# EFR32FG23A010F128GM40 register map
Vendor: Silicon Labs; Series: EFR32; File version: B
Registers are 32-bit, read-write, reset 0x0 unless marked. A register's access mark holds for its fields unless they carry their own. Offsets are from the block's base; [hi:lo] are bit positions; {n}, {i} and the like mark numbered series.

## DMEM_S — DMEM_S Registers
Base 0x400B4000
Same registers: DMEM_NS 0x500B4000
0x00 IPVERSION ro reset 0x1
  [0] IPVERSION — New BitField
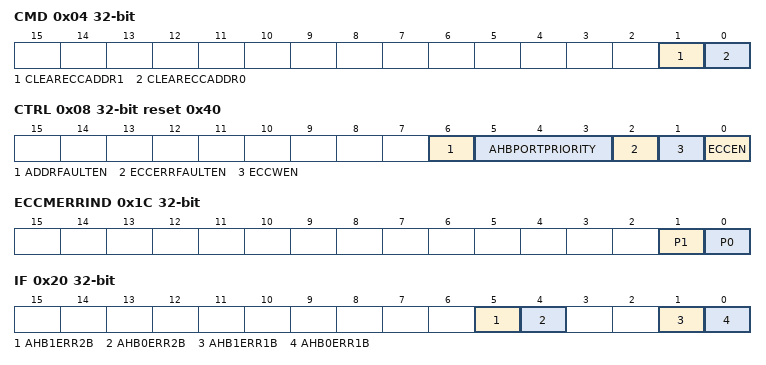
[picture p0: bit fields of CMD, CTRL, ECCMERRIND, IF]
0x04 CMD wo
  [1] CLEARECCADDR1 — Clear ECCERRADDR1
  [0] CLEARECCADDR0 — Clear ECCERRADDR0
0x08 CTRL reset 0x40
  [6] ADDRFAULTEN — Address fault bus fault enable
  [5:3] AHBPORTPRIORITY — AHB port arbitration priority
    0=NONE (No AHB port have raised priority.); 1=PORT0 (AHB port 0 has raised priority.); 2=PORT1 (AHB port 1 has raised priority.)
  [2] ECCERRFAULTEN — ECC Error bus fault enable
  [1] ECCWEN — Enable ECC syndrome writes
  [0] ECCEN — Enable ECC functionality
0x0C ECCERRADDR0 ro
  [31:0] ADDR — ECC Error Address
0x10 ECCERRADDR1 ro
  [31:0] ADDR — ECC Error Address
0x1C ECCMERRIND ro
  [1] P1 — Multiple ECC errors on AHB port 1
  [0] P0 — Multiple ECC errors on AHB port 0
0x20 IF
  [5] AHB1ERR2B — AHB1 2-bit ECC Error Interrupt Flag
  [4] AHB0ERR2B — AHB0 2-bit ECC Error Interrupt Flag
  [1] AHB1ERR1B — AHB1 1-bit ECC Error Interrupt Flag
  [0] AHB0ERR1B — AHB0 1-bit ECC Error Interrupt Flag
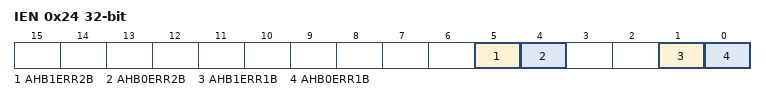
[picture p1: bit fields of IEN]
0x24 IEN
  [5] AHB1ERR2B — AHB1 2-bit ECC Error Interrupt Enable
  [4] AHB0ERR2B — AHB0 2-bit ECC Error Interrupt Enable
  [1] AHB1ERR1B — AHB1 1-bit ECC Error Interrupt Enable
  [0] AHB0ERR1B — AHB0 1-bit ECC Error Interrupt Enable

## LCDRF_S — LCDRF_S Registers
Base 0x400C0000
Same registers: LCDRF_NS 0x500C0000
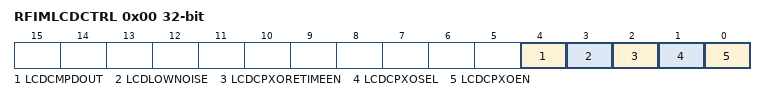
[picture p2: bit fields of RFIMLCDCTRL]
0x00 RFIMLCDCTRL
  [4] LCDCMPDOUT — LCD Comparator Dout
  [3] LCDLOWNOISE
    0=NORMAL (Normal operation); 1=SLOW (slows down slew rate to reduce RF interference at a cost of additional power consumption)
  [2] LCDCPXORETIMEEN — LCD Charge Pump XO Retime Enable
  [1] LCDCPXOSEL — LCD Charge Pump XO Select
    0=INTRCO (Internal LCD CP 10Mhz RC oscillator); 1=HFXODIV (HFXO divided 4 clock)
  [0] LCDCPXOEN — LCD Charge Pump XO Clock Enable

## PFMXPPRF_S — PFMXPPRF_S Registers
Base 0x400C4000
Same registers: PFMXPPRF_NS 0x500C4000
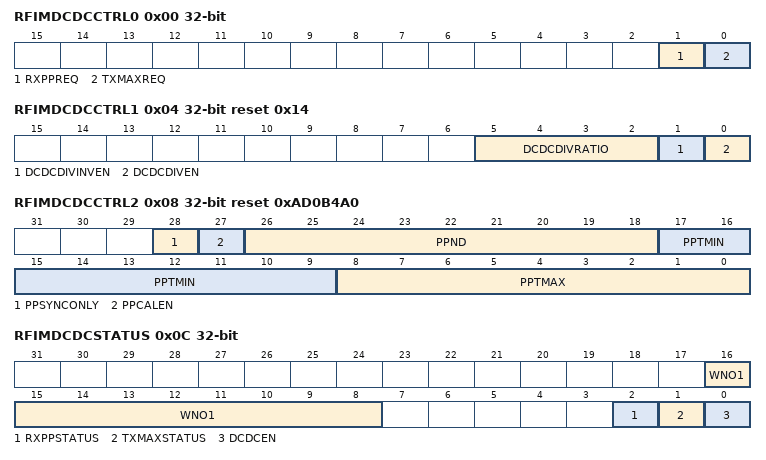
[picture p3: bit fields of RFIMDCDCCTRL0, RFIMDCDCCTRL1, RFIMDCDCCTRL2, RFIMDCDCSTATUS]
0x00 RFIMDCDCCTRL0
  [1] RXPPREQ, [0] TXMAXREQ
0x04 RFIMDCDCCTRL1 reset 0x14
  [5:2] DCDCDIVRATIO
    0=DIVRATIO8 (Dividing master_rf clk by 8, D=50%); 1=DIVRATIO9 (Dividing master_rf clk by 9, D=44.4%); 2=DIVRATIO10 (Dividing master_rf clk by 10, D=40%); 3=DIVRATIO11 (Dividing master_rf clk by 11, D=36.4%); 4=DIVRATIO12 (Dividing master_rf clk by 12, D=50%); 5=DIVRATIO13 (Dividing master_rf clk by 13, D=46.2%); 6=DIVRATIO14 (Dividing master_rf clk by 14, D=42.9%); 7=DIVRATIO15 (Dividing master_rf clk by 15, D=40%); 8=DIVRATIO16 (Dividing master_rf clk by 16, D=50%); 9=DIVRATIO17 (Dividing master_rf clk by 17, D=47.1%); 10=DIVRATIO18 (Dividing master_rf clk by 18, D=44.4%); 11=DIVRATIO19 (Dividing master_rf clk by 19, D=42.1%); 12=DIVRATIO20 (Dividing master_rf clk by 20, D=60%); 13=DIVRATIO21 (Dividing master_rf clk by 21, D=57.1%); 14=DIVRATIO22 (Dividing master_rf clk by 22, D=54.5%); 15=DIVRATIO23 (Dividing master_rf clk by 23, D=52.2%)
  [1] DCDCDIVINVEN — DCDC DIV Inverter Enable
  [0] DCDCDIVEN — DCDC DIV Enable
0x08 RFIMDCDCCTRL2 reset 0xAD0B4A0
  [28] PPSYNCONLY — Pulse Pairing Sync Only
  [27] PPCALEN — Pulse Pairing Calibration Loop Enable
  [26:18] PPND — Pulse Pairing Period
  [17:9] PPTMIN — Pulse Pairing Time Min
  [8:0] PPTMAX — Pulse Pairing Time Max
0x0C RFIMDCDCSTATUS ro
  [16:8] WNO1 — Cal Loop WNO1 value
  [2] RXPPSTATUS
  [1] TXMAXSTATUS
  [0] DCDCEN — DCDC Enable Status
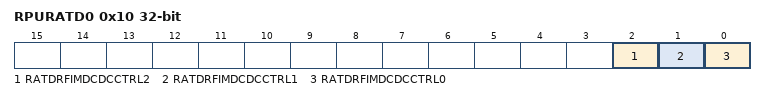
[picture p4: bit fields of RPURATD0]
0x10 RPURATD0 — Protected register address = (RPURATD register index X 32 + RPURATD bit index) X 4.
  [2] RATDRFIMDCDCCTRL2 — RFIMDCDCCTRL2 Protection Bit
  [1] RATDRFIMDCDCCTRL1 — RFIMDCDCCTRL1 Protection Bit
  [0] RATDRFIMDCDCCTRL0 — RFIMDCDCCTRL0 Protection Bit

## SMU_S_CFGNS — SMU_S_CFGNS Registers
Base 0x4400C000
Same registers: SMU_NS_CFGNS 0x5400C000
0x04 NSSTATUS ro
  [0] SMUNSLOCK
    0=UNLOCKED; 1=LOCKED
0x08 NSLOCK wo
  [23:0] SMUNSLOCKKEY
    0xACCE55=UNLOCK (Unlocks Registers)
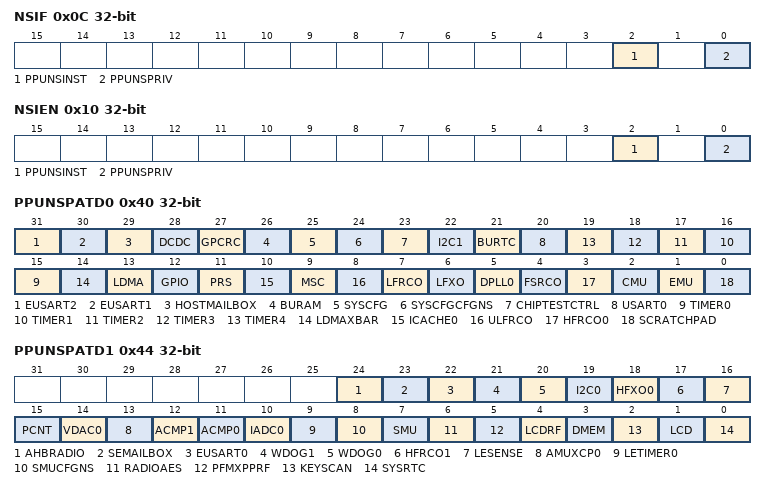
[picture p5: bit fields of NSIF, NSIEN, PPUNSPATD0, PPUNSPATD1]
0x0C NSIF
  [2] PPUNSINST — PPUNS Instruction Interrupt Flag
  [0] PPUNSPRIV — PPUNS Privilege Interrupt Flag
0x10 NSIEN
  [2] PPUNSINST — PPUNS Instruction Interrupt Enable
  [0] PPUNSPRIV — PPUNS Privilege Interrupt Enable
0x40 PPUNSPATD0 — Set peripheral bits to 1 to mark as privileged access only
  [31] EUSART2 — EUSART2 Privileged Access
  [30] EUSART1 — EUSART1 Privileged Access
  [29] HOSTMAILBOX — HOSTMAILBOX Privileged Access
  [28] DCDC — DCDC Privileged Access
  [27] GPCRC — GPCRC Privileged Access
  [26] BURAM — BURAM Privileged Access
  [25] SYSCFG — SYSCFG Privileged Access
  [24] SYSCFGCFGNS — SYSCFGCFGNS Privileged Access
  [23] CHIPTESTCTRL — CHIPTESTCTRL Privileged Access
  [22] I2C1 — I2C1 Privileged Access
  [21] BURTC — BURTC Privileged Access
  [20] USART0 — USART0 Privileged Access
  [n+15] TIMER{n} (n=0..4) — TIMER{n} Privileged Access
  [14] LDMAXBAR — LDMAXBAR Privileged Access
  [13] LDMA — LDMA Privileged Access
  [12] GPIO — GPIO Privileged Access
  [11] PRS — PRS Privileged Access
  [10] ICACHE0 — ICACHE0 Privileged Access
  [9] MSC — MSC Privileged Access
  [8] ULFRCO — ULFRCO Privileged Access
  [7] LFRCO — LFRCO Privileged Access
  [6] LFXO — LFXO Privileged Access
  [5] DPLL0 — DPLL0 Privileged Access
  [4] FSRCO — FSRCO Privileged Access
  [3] HFRCO0 — HFRCO0 Privileged Access
  [2] CMU — CMU Privileged Access
  [1] EMU — EMU Privileged Access
  [0] SCRATCHPAD — SCRATCHPAD Privileged Access
0x44 PPUNSPATD1 — Set peripheral bits to 1 to mark as privileged access only
  [24] AHBRADIO — AHBRADIO Privileged Access
  [23] SEMAILBOX — SEMAILBOX Privileged Access
  [22] EUSART0 — EUSART0 Privileged Access
  [21] WDOG1 — WDOG1 Privileged Access
  [20] WDOG0 — WDOG0 Privileged Access
  [19] I2C0 — I2C0 Privileged Access
  [18] HFXO0 — HFXO0 Privileged Access
  [17] HFRCO1 — HFRCO1 Privileged Access
  [16] LESENSE — LESENSE Privileged Access
  [15] PCNT — PCNT Privileged Access
  [14] VDAC0 — VDAC0 Privileged Access
  [13] AMUXCP0 — AMUXCP0 Privileged Access
  [12] ACMP1 — ACMP1 Privileged Access
  [11] ACMP0 — ACMP0 Privileged Access
  [10] IADC0 — IADC0 Privileged Access
  [9] LETIMER0 — LETIMER0 Privileged Access
  [8] SMUCFGNS — SMUCFGNS Privileged Access
  [7] SMU — SMU Privileged Access
  [6] RADIOAES — RADIOAES Privileged Access
  [5] PFMXPPRF — PFMXPPRF Privileged Access
  [4] LCDRF — LCDRF Privileged Access
  [3] DMEM — DMEM Privileged Access
  [2] KEYSCAN — KEYSCAN Privileged Access
  [1] LCD — LCD Privileged Access
  [0] SYSRTC — SYSRTC Privileged Access
0x140 PPUNSFS ro
  [7:0] PPUFSPERIPHID — Peripheral I
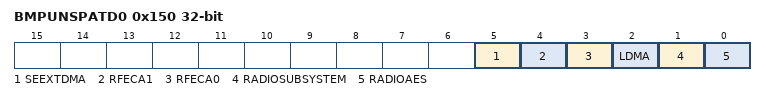
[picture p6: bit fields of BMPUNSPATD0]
0x150 BMPUNSPATD0
  [5] SEEXTDMA — SEEXTDMA privileged mode
  [4] RFECA1 — RFECA1 privileged mode
  [3] RFECA0 — RFECA0 privileged mode
  [2] LDMA — MCU LDMA privileged mode
  [1] RADIOSUBSYSTEM — RADIO subsystem masters privileged mode
  [0] RADIOAES — RADIO AES DMA privileged mode
